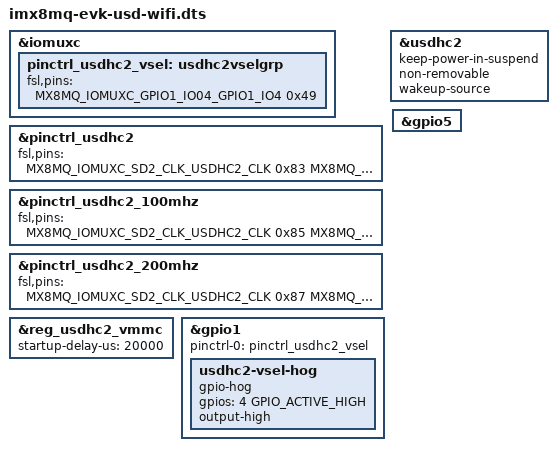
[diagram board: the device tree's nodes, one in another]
// SPDX-License-Identifier: (GPL-2.0 OR MIT)
/*
 * Copyright 2020 NXP
 */

/dts-v1/;

#include "imx8mq-evk.dts"

&iomuxc {
	pinctrl_usdhc2_vsel: usdhc2vselgrp {
		fsl,pins = <
			MX8MQ_IOMUXC_GPIO1_IO04_GPIO1_IO4		0x49
		>;
	};
};

&pinctrl_usdhc2 {
	fsl,pins = <
		MX8MQ_IOMUXC_SD2_CLK_USDHC2_CLK			0x83
		MX8MQ_IOMUXC_SD2_CMD_USDHC2_CMD			0xc3
		MX8MQ_IOMUXC_SD2_DATA0_USDHC2_DATA0		0xc3
		MX8MQ_IOMUXC_SD2_DATA1_USDHC2_DATA1		0xc3
		MX8MQ_IOMUXC_SD2_DATA2_USDHC2_DATA2		0xc3
		MX8MQ_IOMUXC_SD2_DATA3_USDHC2_DATA3		0xc3
	>;
};

&pinctrl_usdhc2_100mhz {
	fsl,pins = <
		MX8MQ_IOMUXC_SD2_CLK_USDHC2_CLK			0x85
		MX8MQ_IOMUXC_SD2_CMD_USDHC2_CMD			0xc5
		MX8MQ_IOMUXC_SD2_DATA0_USDHC2_DATA0		0xc5
		MX8MQ_IOMUXC_SD2_DATA1_USDHC2_DATA1		0xc5
		MX8MQ_IOMUXC_SD2_DATA2_USDHC2_DATA2		0xc5
		MX8MQ_IOMUXC_SD2_DATA3_USDHC2_DATA3		0xc5
	>;
};

&pinctrl_usdhc2_200mhz {
	fsl,pins = <
		MX8MQ_IOMUXC_SD2_CLK_USDHC2_CLK			0x87
		MX8MQ_IOMUXC_SD2_CMD_USDHC2_CMD			0xc7
		MX8MQ_IOMUXC_SD2_DATA0_USDHC2_DATA0		0xc7
		MX8MQ_IOMUXC_SD2_DATA1_USDHC2_DATA1		0xc7
		MX8MQ_IOMUXC_SD2_DATA2_USDHC2_DATA2		0xc7
		MX8MQ_IOMUXC_SD2_DATA3_USDHC2_DATA3		0xc7
	>;
};

&usdhc2 {
	/delete-property/ cd-gpios;
	keep-power-in-suspend;
	non-removable;
	wakeup-source;
};

&reg_usdhc2_vmmc {
	/* this property is used for sd card SD3.0 mode, no need for SDIO wifi  */
	/delete-property/ off-on-delay-us;
	/*
	 * IW612 wifi chip needs more delay than other wifi chips to complete
	 * the host interface initialization after power up, otherwise the
	 * internal state of IW612 may be unstable, resulting in the failure of
	 * the SDIO3.0 switch voltage.
	 */
	startup-delay-us = <20000>;
};

&gpio1 {
	pinctrl-names = "default";
	pinctrl-0 = <&pinctrl_usdhc2_vsel>;

	usdhc2-vsel-hog {
		gpio-hog;
		gpios = <4 GPIO_ACTIVE_HIGH>;
		output-high;
	};
};

&gpio5 {
	/delete-node/ wl-reg-on-hog; /* disable the on-board wifi */
};
